# DA1470x register map
Vendor: Dialog; Series: DA1470x; File version: 1.2
CPU: CM33 r0p2, little endian, MPU, FPU, DSP, VTOR, 4 interrupt priority bits
Registers are 32-bit, read-write, reset 0x0 unless marked. A register's access mark holds for its fields unless they carry their own. Offsets are from the block's base; [hi:lo] are bit positions; {n}, {i} and the like mark numbered series.

## OQSPIF — OQSPIF registers
Base 0x36000000
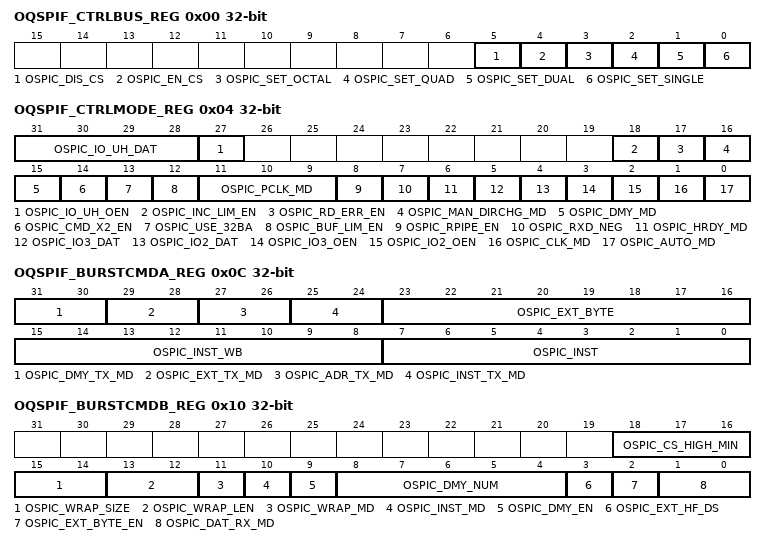
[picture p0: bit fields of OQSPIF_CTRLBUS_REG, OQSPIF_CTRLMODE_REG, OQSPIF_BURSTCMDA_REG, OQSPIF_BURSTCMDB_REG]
0x00 OQSPIF_CTRLBUS_REG — SPI Bus control register for the Manual mode
  [5] OSPIC_DIS_CS wo — Write 1 to disable the chip select (active low) when the controller is in Manual mode.
  [4] OSPIC_EN_CS wo — Write 1 to enable the chip select (active low) when the controller is in Manual mode.
  [3] OSPIC_SET_OCTAL wo — Write 1 to set the bus mode in Octal mode when the controller is in Manual mode.
  [2] OSPIC_SET_QUAD wo — Write 1 to set the bus mode in Quad mode when the controller is in Manual mode.
  [1] OSPIC_SET_DUAL wo — Write 1 to set the bus mode in Dual mode when the controller is in Manual mode.
  [0] OSPIC_SET_SINGLE wo — Write 1 to set the bus mode in Single SPI mode when the controller is in Manual mode.
0x04 OQSPIF_CTRLMODE_REG (reset mask 0x7FFFFFFF) — Mode Control register
  [31:28] OSPIC_IO_UH_DAT — The value of OSPI_IO4-7 pads if OSPI_IO_UH_OEN is 1
  [27] OSPIC_IO_UH_OEN — Forces the output enable for the upper half of the OSPI bus (OSPI_IO4-7). Set this bit to 1 only in SPI, Dual or Quad SPI mode to control the upper half of the OSPI bus. When the Octal SPI is enabled in the flash device, set this bit to zero. 0: The OSPI_IO4-7 pad direction is decided by the controller. 1: The OSPI_IO4-7 pad are outputs. The output values are defined by the corresponding OSPIC_IO_UH_DAT bits.
  [18] OSPIC_INC_LIM_EN — This bit has meaning only for the read in auto mode and only when the read access in the AHB bus is an incremental bust of unspecified length. 0: The length of the burst is considered as unspecified. The access in the flash device will be implemented as is defined by the OSPIC BUF_LIM_EN bit. 1: The length of the burst is considered as equal to 8-bytes. The access in the flash device will be implemented by the controller as one or more different bursts, until to be served the access in the AHB bus. Each burst in the flash device will have maximum length of 8 bytes. The setting OSPIC_INC_LIM_EN=1 is useful if we know that the masters that make use of the incremental burst of unspecified length, require no more than 8 bytes.
  [17] OSPIC_RD_ERR_EN — Controls the generation of AHB bus error response when a read is performed in the address space where the flash device is mapped and the Auto mode is not enabled. 0: The controller ignores the access. There is no error response due to the read access. 1: The controller responds with an AHB error response.
  [16] OSPIC_MAN_DIRCHG_MD — Selection of the direction change method in manual mode. 0 : the bus direction goes to input after each access 1 : the bus direction goes to input only after a dummy access
  [15] OSPIC_DMY_MD — Defines the clock cycle where the bus will turn in Hi-z during the transmission of dummy bytes. This is applicable in both Manual and Auto mode. 0 : the bus will become Hi-Z on the last clock 1 : the bus will become Hi-Z on the last two clocks
  [14] OSPIC_CMD_X2_EN — Defines the number of bytes that consist the instruction code in the command sequences that produced by the OSPIC during Auto mode. 0 : The instruction code is one byte only. 1 : The instruction code is two bytes. The second byte of the instruction code is the inverse of the first byte. The command sequence that is produced by the OSPIC_BURSTBRK_REG is not affected by this setting.
  [13] OSPIC_USE_32BA — Controls the length of the address that the external memory device uses. 0: The external memory device uses 24 bits address. 1: The external memory device uses 32 bits address. The controller uses this bit in order to decide the number of the address bytes that has to transfer to the external device during Auto mode.
  [12] OSPIC_BUF_LIM_EN — This bit has meaning only for the read in auto mode. Defines the behavior of the controller when the internal buffer is full and there are more data to be retrieved for the current burst. 0: The access in the flash device is not terminated when the internal buffer has no empty space. In this case the OSPI_SCK clock is blocked until to free space in the internal buffer. 1: The access in the flash device is terminated when the internal buffer has no empty space. A new access in the flash device will be initiated when will be requested addresses that are not present in the internal buffer. In both cases the access in the flash device is terminated when there is no any read request.
  [11:9] OSPIC_PCLK_MD — Read pipe clock delay relative to the falling edge of OSPI_SCK. Refer to OSPI Timing for timing parameters and recommended values: 0 to 7
  [8] OSPIC_RPIPE_EN — Controls the use of the data read pipe. 0: The read pipe is disabled; the sampling clock is defined according to the OSPIC_RXD_NEG setting. 1: The read pipe is enabled. The delay of the sampling clock is defined according to the OSPICI_PCLK_MD setting. (Recommended)
  [7] OSPIC_RXD_NEG — Defines the clock edge that is used for the capturing of the received data, when the read pipe is not active (OSPIC_RPIPE_EN = 0). 0: Sampling of the received data with the positive edge of the OSPI_SCK 1: Sampling of the received data with the negative edge of the OSPI_SCK The internal OSPI_SCK clock that is used by the controller for the capturing of the received data has a skew in respect of the OSPI_SCK that is received by the external memory device. In order to be improved the timing requirements of the read path, the controller supports a read pipe register with programmable clock delay. See also the OSPIC_RPIPE_EN register.
  [6] OSPIC_HRDY_MD — This configuration bit is useful when the frequency of the OSPI clock is much lower than the clock of the AMBA bus, in order to not locks the AMBA bus for a long time. 0: Adds wait states via hready signal when an access is performed on the OSPIC_CTRLBUS_REG, OSPIC_WRITEDATA, OSPIC_READDATA and OSPIC_DUMMYDATA registers. It is not needed to check the OSPIC_BUSY of the OSPIC_STATUS_REG. 1: The controller don't adds wait states via the hready signal, when is performed access on the OSPIC_CTRLBUS_REG, OSPIC_WRITEDATA, OSPIC_READDATA and OSPIC_DUMMYDATA registers. The OSPIC_BUSY bit of the OSPIC_STATUS_REG must be checked in order to be detected the completion of the requested access. It is applicable only when the controller is in Manual mode. In the case of the Auto mode, the controller always adds wait states via the hready signal.
  [5] OSPIC_IO3_DAT — The value of OSPI_IO3 pad if OSPI_IO3_OEN is 1
  [4] OSPIC_IO2_DAT — The value of OSPI_IO2 pad if OSPI_IO2_OEN is 1
  [3] OSPIC_IO3_OEN — Forces the output enable of the OSPI_IO3. Set this bit to 1 only in SPI or Dual SPI mode to control the /HOLD signal. When the Quad or Octal SPI is enabled in the flash device, set this bit to zero. 0: The OSPI_IO3 pad direction is decided by the controller. 1: The OSPI_IO3 pad is output. The output value is defined by the OSPIC_IO3_DAT.
  [2] OSPIC_IO2_OEN — Forces the output enable of the OSPI_IO2. Set this bit to 1 only in SPI or Dual SPI mode to control the /WP signal. When the Quad or Octal SPI is enabled in the flash device, set this bit to zero. 0: The OSPI_IO2 pad direction is decided by the controller. 1: The OSPI_IO2 pad is output. The output value is defined by the OSPIC_IO2_DAT.
  [1] OSPIC_CLK_MD — Mode of the generated OSPI_SCK clock 0: Use Mode 0 for the OSPI_CLK. The OSPI_SCK is low when OSPI_CS is high. 1: Use Mode 3 for the OSPI_CLK. The OSPI_SCK is high when OSPI_CS is high.
  [0] OSPIC_AUTO_MD — Mode of operation 0: The Manual Mode is selected. 1: The Auto Mode is selected. During an erasing the OSPIC_AUTO_MD goes in read only mode (see OSPIC_ERASE_EN)
0x08 OQSPIF_RECVDATA_REG (reset mask 0x7FFFFFFF) — Received data for the Manual mode
  [31:0] OSPIC_RECVDATA ro — This register contains the received data when the OSPIC_READDATA_REG register is used in Manual mode, in order to be retrieved data from the external memory device and OSPIC_HRDY_MD=1 && OSPIC_BUSY=0.
0x0C OQSPIF_BURSTCMDA_REG (reset mask 0x7FFFFFFF) — The way of reading in Auto mode (command register A)
  [31:30] OSPIC_DMY_TX_MD — It describes the mode of the SPI bus during the Dummy bytes phase. 0x0: Single SPI 0x1: Dual 0x2: Quad 0x3: Octal
  [29:28] OSPIC_EXT_TX_MD — It describes the mode of the SPI bus during the Extra Byte phase. 0x0: Single SPI 0x1: Dual 0x2: Quad 0x3: Octal
  [27:26] OSPIC_ADR_TX_MD — It describes the mode of the SPI bus during the address phase. 0x0: Single SPI 0x1: Dual 0x2: Quad 0x3: Octal
  [25:24] OSPIC_INST_TX_MD — It describes the mode of the SPI bus during the instruction phase. 0x0: Single SPI 0x1: Dual 0x2: Quad 0x3: Octal
  [23:16] OSPIC_EXT_BYTE — The value of an extra byte which will be transferred after address (only if OSPIC_EXT_BYTE_EN= 1). Usually this is the Mode Bits in Dual/Quad/Octal SPI I/O instructions.
  [15:8] OSPIC_INST_WB — Instruction Value for Wrapping Burst. This value is the selected instruction when OSPIC_WRAP_MD is equal to 1 and the access is a wrapping burst of length and size described by the bit fields OSPIC_WRAP_LEN and OSPIC_WRAP_SIZE respectively.
  [7:0] OSPIC_INST — Instruction Value for Incremental Burst or Single read access. This value is the selected instruction at the cases of incremental burst or single read access. Also this value is used when a wrapping burst is not supported (OSPIC_WRAP_MD)
0x10 OQSPIF_BURSTCMDB_REG — The way of reading in Auto mode (command register B)
  [18:16] OSPIC_CS_HIGH_MIN — Between the transmissions of two different instructions to the flash memory, the SPI bus stays in idle state (OSPI_CS high) for at least this number of OSPI_SCK clock cycles. See the OSPIC_ERS_CS_HI register for some exceptions.
  [15:14] OSPIC_WRAP_SIZE — It describes the selected data size of a wrapping burst (OSPIC_WRAP_MD). 0x0: byte access (8-bits) 0x1: half word access (16 bits) 0x2: word access (32-bits) 0x3: Reserved
  [13:12] OSPIC_WRAP_LEN — It describes the selected length of a wrapping burst (OSPIC_WRAP_MD). 0x0: 4 beat wrapping burst 0x1: 8 beat wrapping burst 0x2: 16 beat wrapping burst 0x3: Reserved
  [11] OSPIC_WRAP_MD — Wrap mode 0: The OSPIC_INST is the selected instruction at any access. 1: The OSPIC_INST_WB is the selected instruction at any wrapping burst access of length and size described by the registers OSPIC_WRAP_LEN and OSPIC_WRAP_SIZE respectively. In all other cases the OSPIC_INST is the selected instruction. Use this feature only when the serial FLASH memory supports a special instruction for wrapping burst access.
  [10] OSPIC_INST_MD — Instruction mode 0: Transmit instruction at any burst access. 1: Transmit instruction only in the first access after the selection of Auto Mode.
  [9] OSPIC_DMY_EN — Dummy bytes enable 0: Don't send the dummy bytes 1: Send the dummy bytes. The number of the dummy bytes is defined by the OSPIC_DMY_NUM.
  [8:4] OSPIC_DMY_NUM — Number of dummy bytes (minus 1). Can be set 1 up to 32 dummy bytes (values 0 up to 31). The dummy bytes are appied only when OSPIC_DMY_EN=1.
  [3] OSPIC_EXT_HF_DS — Extra half disable output 0: if OSPIC_EXT_BYTE_EN=1, is transmitted the complete OSPIC_EXT_BYTE 1: if OSPIC_EXT_BYTE_EN=1, the output is disabled (hi-z) during the transmission of bits [3:0] of OSPIC_EXT_BYTE. This setting has no meaning if the extra byte is transferred in Octal mode. In this case keep this bit to zero value.
  [2] OSPIC_EXT_BYTE_EN — Extra byte enable 0: Don't send the OSPIC_EXT_BYTE 1: Send the OSPIC_EXT_BYTE
  [1:0] OSPIC_DAT_RX_MD — It describes the mode of the SPI bus during the data phase. 0x0: Single SPI 0x1: Dual 0x2: Quad 0x3: Octal
0x14 OQSPIF_STATUS_REG — The status register of the OSPI controller
  [0] OSPIC_BUSY ro — The status of the SPI Bus. 0: The SPI Bus is idle 1: The SPI Bus is active. Read data, write data or dummy data activity is in progress. Has meaning only in Manual mode and only when OSPIC_HRDY_MD = 1.
0x18 OQSPIF_WRITEDATA_REG (reset mask 0x7FFFFFFF) — Write data to SPI Bus for the Manual mode
  [31:0] OSPIC_WRITEDATA wo — Writing to this register is generating a data transfer from the controller to the external memory device. The data written in this register, is then transferred to the memory using the selected mode of the SPI bus (Single SPI, Dual SPI, Quad SPI or Octal SPI). The data size of the access to this register can be 32-bits / 16-bits/ 8-bits and is equal to the number of the transferred bits. This register has meaning only when the controller is in Manual mode.
0x1C OQSPIF_READDATA_REG (reset mask 0x7FFFFFFF) — Read data from SPI Bus for the Manual mode
  [31:0] OSPIC_READDATA ro — A read access at this register generates a data transfer from the external memory device to the OSPIC controller. The data is transferred using the selected mode of the SPI bus (Single SPI, Dual SPI, Quad SPI or Octal SPI). The data size of the access to this register can be 32-bits / 16-bits / 8-bits and is equal to the number of the transferred bits. This register has meaning only when the controller is in Manual mode.
0x20 OQSPIF_DUMMYDATA_REG (reset mask 0x7FFFFFFF) — Send dummy clocks to SPI Bus for the Manual mode
  [31:0] OSPIC_DUMMYDATA wo — Writing to this register generates a number of clock pulses to the SPI bus. During the last clock of this activity in the SPI bus, the OSPI_IOx data pads are in hi-z state (see also the OSPIC_DMY_MD). The data size of the access to this register can be 32-bits / 16-bits/ 8-bits. The number of generated pulses is equal to: (size of AHB bus access) / (size of SPI bus). The size of SPI bus is equal to 1, 2, 4 or 8 for Single, Dual, Quad or Octal SPI mode respectively. This register has meaning only when the controller is in Manual mode.
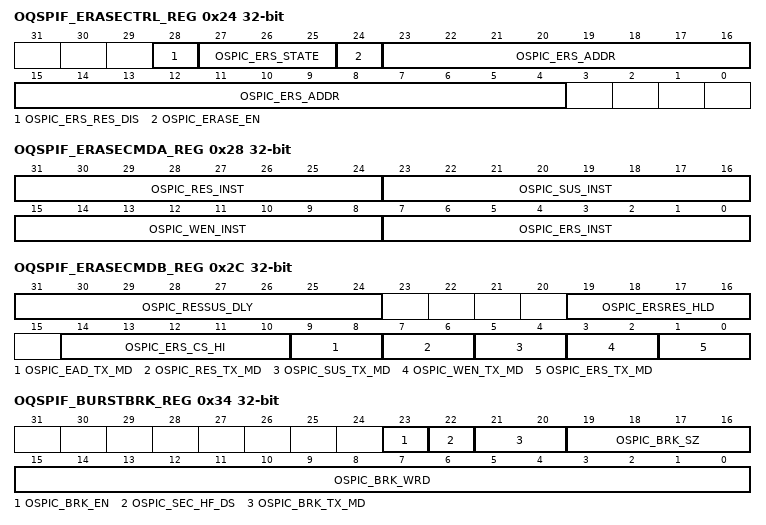
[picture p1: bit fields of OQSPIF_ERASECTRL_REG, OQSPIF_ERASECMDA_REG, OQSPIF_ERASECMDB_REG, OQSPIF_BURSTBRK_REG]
0x24 OQSPIF_ERASECTRL_REG — OSPI Erase control register
  [28] OSPIC_ERS_RES_DIS — This configuration bit has meaning when an erase has been suspended. Normally the erase will be resumed when the flash will stay idle (without read accesses) for a predefined number of clock cycles (see OSPIC_ERASECMDB_REG [OSPIC_ERSRES_HLD]). By setting this bit the execution of the erase resume process can be postponed. 0: A suspended erase will be resumed based on the setting in the OSPIC_ERSRES_HLD. 1: The erase will not be resumed even after the expiration of the OSPIC_ERSRES_HLD. The erase can be resumed again only when the OSPIC_ERS_RES_DIS=0.
  [27:25] OSPIC_ERS_STATE ro — It shows the progress of sector/block erasing (read only). 0x0: No Erase. 0x1: Pending erase request 0x2: Erase procedure is running 0x3: Suspended Erase procedure 0x4: Finishing the Erase procedure 0x5..0x7: Reserved
  [24] OSPIC_ERASE_EN — During Manual mode (OSPIC_AUTO_MD = 0). This bit is in read only mode. During Auto mode (OSPIC_AUTO_MD = 1). To request the erasing of the block/sector (OSPIC_ERS_ADDR, 12'b0) write 1 to this bit. This bit is cleared automatically with the end of the erasing. Until the end of erasing the OSPIC_ERASE_EN remains in read only mode. During the same time interval the controller remains in Auto Mode (OSPIC_AUTO_MD goes in read only mode).
  [23:4] OSPIC_ERS_ADDR — Defines the address of the block/sector that is requested to be erased. If OSPIC_USE_32BA = 0 (24 bits addressing), bits OSPIC_ERASECTRL_REG[23-12] determine the block/ sector address bits [23-12]. The OSPIC_ERASECTRL_REG[11-4] are ignored by the controller. If OSPIC_USE_32BA = 1 (32 bits addressing) bits OSPIC_ERASECTRL_REG[23-4] determine the block / sectors address bits [31:12]
0x28 OQSPIF_ERASECMDA_REG (reset mask 0x7FFFFFFF) — The way of erasing in Auto mode (command register A)
  [31:24] OSPIC_RES_INST — The code value of the erase resume instruction
  [23:16] OSPIC_SUS_INST — The code value of the erase suspend instruction.
  [15:8] OSPIC_WEN_INST — The code value of the write enable instruction.
  [7:0] OSPIC_ERS_INST — The code value of the erase instruction.
0x2C OQSPIF_ERASECMDB_REG (reset mask 0x7FFFFFFF) — The way of erasing in Auto mode (command register B)
  [31:24] OSPIC_RESSUS_DLY — Defines a timer that counts the minimum allowed delay between an erase suspend command and the previous erase resume command (or the initial erase command). 0: Don't wait. The controller starts immediately to suspend the erase procedure. 1..255: The controller waits for at least this number of 222kHz clock cycles before the suspension of erasing. Time starts counting after the end of the previous erase resume command (or the initial erase command)
  [19:16] OSPIC_ERSRES_HLD — The controller must stay without flash memory reading requests for this number of AMBA hclk clock cycles, before to perform the command of erase or erase resume 15 - 0
  [14:10] OSPIC_ERS_CS_HI — After the execution of instructions: write enable, erase, erase suspend and erase resume, the OSPI_CS remains high for at least this number of OSPI bus clock cycles.
  [9:8] OSPIC_EAD_TX_MD — The mode of the OSPI Bus during the address phase of the erase instruction 0x0: Single 0x1: Dual 0x2: Quad 0x3: Octal
  [7:6] OSPIC_RES_TX_MD — The mode of the OSPI Bus during the transmission of the resume instruction 0x0: Single 0x1: Dual 0x2: Quad 0x3: Octal
  [5:4] OSPIC_SUS_TX_MD — The mode of the OSPI Bus during the transmission of the suspend instruction. 0x0: Single 0x1: Dual 0x2: Quad 0x3: Octal
  [3:2] OSPIC_WEN_TX_MD — The mode of the OSPI Bus during the transmission of the write enable instruction. 0x0: Single 0x1: Dual 0x2: Quad 0x3: Octal
  [1:0] OSPIC_ERS_TX_MD — The mode of the OSPI Bus during the instruction phase of the erase instruction 0x0: Single 0x1: Dual 0x2: Quad 0x3: Octal
0x30 OQSPIF_ERASECMDC_REG — The way of erasing in Auto mode (command register C)
  [5:0] OSPIC_SUSSTS_DLY — Defines a timer that counts the minimum allowed delay between an erase suspend command and the next read status command. 0: Don't wait. The controller starts immediately to read the status of the flash device. 1..63: The controller waits for at least this number of 222kHz clock cycles before to read the status of the flash device. Time starts counting when the erase resume command is applied.
0x34 OQSPIF_BURSTBRK_REG — Read break sequence in Auto mode
  [23] OSPIC_BRK_EN — Controls the application of a special command (read burst break sequence) that is used in order to force the device to abandon the continuous read mode. 0: The special command is not applied 1: The special command is applied This special command is applied by the controller to the external device under the following conditions: - the controller is in Auto mode - the OSPIC_INST_MD = 1 - the previous command that has been applied in the external device was read - the controller want to apply to the external device a command different than the read.
  [22] OSPIC_SEC_HF_DS — Disable output during the transmission of the second half (OSPIC_BRK_WRD[3:0]). Setting this bit is only useful if OSPIC_BRK_EN =1 and OSPIC_BRK_SZ >= 1. It is not applicable when the sequence is transferred in Octal mode (OSPIC_BRK_TX_MD=3). 0: The controller drives the OSPI bus during the transmission of the OSPIC_BRK_WRD[3:0]. 1: The controller leaves the OSPI bus in Hi-Z during the transmission of the OSPIC_BRK_WORD[3:0].
  [21:20] OSPIC_BRK_TX_MD — The mode of the OSPI Bus during the transmission of the burst break sequence. 0x0: Single 0x1: Dual 0x2: Quad 0x3: Octal
  [19:16] OSPIC_BRK_SZ — The size of Burst Break Sequence 0: One byte (Send OSPIC_BRK_WRD[15:8]) 1: Two bytes (Send OSPIC_BRK_WRD[15:0]) 2-15: Three up to 16 bytes will be transferred. All the bytes that will be transferred will have the value of the OSPIC_BRK_WRD[15:8], except of the last byte that will be the OSPIC_BRK_WRD[7:0].
  [15:0] OSPIC_BRK_WRD — This is the value of a special command (read burst break sequence) that is applied by the controller to the external memory device, in order to force the memory device to abandon the continuous read mode.
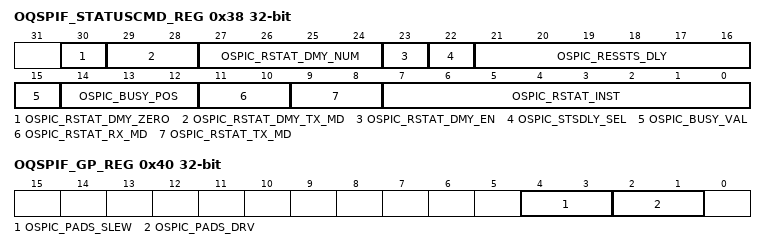
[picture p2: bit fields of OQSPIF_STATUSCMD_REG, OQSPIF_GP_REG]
0x38 OQSPIF_STATUSCMD_REG — The way of reading the status of external device in Auto mode
  [30] OSPIC_RSTAT_DMY_ZERO — Defines the value of that is transferred on the OSPI bus during the phase of the dummy bytes. 0: The controller keeps the data in the bus unchanged, until to change the bus direction in input mode. 1: Forces the dummy bytes to get the zero value (only for the cycles that are not in input mode). Only the IO pins that are related with the transfer mode of the dummy bytes (OSPIC_RSTAT_DMY_TX_MD) will get the zero value.
  [29:28] OSPIC_RSTAT_DMY_TX_MD — It describes the mode of the OSPI bus during the dummy bytes phase. 0x0: Single SPI 0x1: Dual 0x2: Quad 0x3: Octal
  [27:24] OSPIC_RSTAT_DMY_NUM — Number of dummy bytes (minus 1). Can be set 1 up to 16 dummy bytes (values 0 up to 15). The dummy bytes are applied only when OSPIC_RSTAT_DMY_EN=1.
  [23] OSPIC_RSTAT_DMY_EN — Enables the transmission of dummy bytes, immediately after the instruction code of the read status command. 0: Don't send the dummy bytes 1: Send the dummy bytes. The number of the dummy bytes is defined by the OSPIC_RSTAT_DMY_NUM.
  [22] OSPIC_STSDLY_SEL — Defines the timer which is used to count the delay that it has to wait before to read the FLASH Status Register, after an erase or an erase resume command. 0: The delay is controlled by the OSPIC_RESSTS_DLY which counts on the OSPI_CLK clock. 1: The delay is controlled by the OSPIC_RESSUS_DLY which counts on the 222 kHz clock.
  [21:16] OSPIC_RESSTS_DLY — Defines a timer that counts the minimum required delay between the reading of the status register and of the previous erase or erase resume instruction. 0: Don't wait. The controller starts to reading the Flash memory status register immediately. 1..63: The controller waits for at least this number of OSPI_CLK cycles and afterwards it starts to reading the Flash memory status register. The timer starts to count after the end of the previous erase or erase resume command. The actual timer that will be used by the controller before the reading of the Flash memory status register is defined by the OSPIC_STSDLY_SEL.
  [15] OSPIC_BUSY_VAL — Defines the value of the Busy bit which means that the flash is busy. 0: The flash is busy when the Busy bit is equal to 0. 1: The flash is busy when the Busy bit is equal to 1.
  [14:12] OSPIC_BUSY_POS — It describes who from the bits of status represents the Busy bit (7 - 0).
  [11:10] OSPIC_RSTAT_RX_MD — The mode of the OSPI Bus during the receive status phase of the read status instruction 0x0: Single 0x1: Dual 0x2: Quad 0x3: Octal
  [9:8] OSPIC_RSTAT_TX_MD — The mode of the OSPI Bus during the instruction phase of the read status instruction. 0x0: Single 0x1: Dual 0x2: Quad 0x3: Octal
  [7:0] OSPIC_RSTAT_INST — The code value of the read status instruction. It is transmitted during the instruction phase of the read status instruction.
0x3C OQSPIF_CHCKERASE_REG (reset mask 0x7FFFFFFF) — Check erase progress in Auto mode
  [31:0] OSPIC_CHCKERASE wo — Writing any value to this register during erasing, forces the controller to read the flash memory status register. Depending on the value of the Busy bit, it updates the OSPIC_ERASE_EN.
0x40 OQSPIF_GP_REG — OSPI General Purpose control register
  [4:3] OSPIC_PADS_SLEW — QSPI pads slew rate control. Indicative values under certain conditions: 0: Rise=1.7 V/ns, Fall=1.9 V/ns (weak) 1: Rise=2.0 V/ns, Fall=2.3 V/ns 2: Rise=2.3 V/ns, Fall=2.6 V/ns 3: Rise=2.4 V/ns, Fall=2.7 V/ns (strong) Conditions: FLASH pin capacitance 6 pF, Vcc=1.8V, T=25C and Idrive=16mA.
  [2:1] OSPIC_PADS_DRV — QSPI pads drive current 0: 4 mA 1: 8 mA 2: 12 mA 3: 16 mA
0x100 OQSPIF_CTR_CTRL_REG — Control register for the decryption engine of the OSPIC
  [0] OSPIC_CTR_EN — Controls the AES-CTR decryption feature of the OSPIC, which enables the decryption (on-the-fly) of the data that are retrieved from the flash memory device. 0: The AES-CTR decryption is disabled. 1: The controller will decrypt the content of the flash memory device that is placed in the address space that is defined by the OSPIC_CTR_SADDR_REG and OSPIC_CTR_EADDR_REG registers. The data that are placed outside the previous space are not decrypted by the OSPIC. The decryption is performed by using the AES-CTR algorithm. The AES key is defined by the OSPIC_CTR_KEY_x_y_REG registers and the nonce value by the OSPIC_CTR_NONCE_x_y_REG registers. This configuration bit has meaning only while the controller is in Auto mode. The on-the-fly decryption is not provided in Manual mode.
0x104 OQSPIF_CTR_SADDR_REG (reset mask 0x7FFFFFFF) — Start address of the encrypted content in the OSPI flash
  [31:10] OSPIC_CTR_SADDR — Defines the bits [31:10] of the start address in the flash memory, where an encrypted image is placed. The bits [9:0] are considered always as zero. This has meaning only when the decryption is active. See also the register OSPIC_CTR_CTRL_REG[OSPIC_CTR_EN].
0x108 OQSPIF_CTR_EADDR_REG reset 0x3FF (reset mask 0x7FFFFFFF) — End address of the encrypted content in the OSPI flash
  [31:10] OSPIC_CTR_EADDR — Defines the bits [31:10] of the end address in the flash memory, where an encrypted image is placed. The bits [9:0] are considered always as 0x3ff. This has meaning only when the decryption is active. See also the register OSPIC_CTR_CTRL_REG[OSPIC_CTR_EN].
0x10C OQSPIF_CTR_NONCE_0_3_REG (reset mask 0x7FFFFFFF) — Nonce bytes 0 to 3 for the AES-CTR algorithm
  [31:0] OSPIC_CTR_NONCE_0_3 — Defines the 8 bytes of the nonce value (N0 - N7) that is used by the AES-CTR algorithm in order to be constructed the counter block (CTRB). The total size of the counter block is 128 bits or 16 bytes : CTRB0 CTRB1 CTRB2 CTRB3...CTRB14 CTRB15. The first 8 bytes (CTRB0 - CTRB7) of the counter block consisted by the nonce value. The next 8 bytes of the counter block (CTRB8-CTRB15), are produced automatically by the hardware based on the address offset inside the encrypted image, from where are retrieved the requested data. The mapping of the nonce bytes to the corresponding OSPIC_NONCE_X_Y_REG registers is the following : {CTRB0, CTRB1, CTRB2, CTRB3} = {N0, N1, N2, N3} = OSPIC_NONCE_0_3_REG[31:0] {CTRB4, CTRB5, CTRB6, CTRB7} = {N4, N5, N6, N7} = OSPIC_NONCE_4_7_REG[31:0] All these registers make sense only when OSPIC_CTR_CTRL_REG[OSPIC_CTR_EN] = 1. Do not perform access to an encrypted address range while the updating process of the nonce value is in progress.
0x110 OQSPIF_CTR_NONCE_4_7_REG (reset mask 0x7FFFFFFF) — Nonce bytes 4 to 7 for the AES-CTR algorithm
  [31:0] OSPIC_CTR_NONCE_4_7 — See the description in the OSPIC_NONCE_0_3.
0x114 OQSPIF_CTR_KEY_0_3_REG (reset mask 0x7FFFFFFF) — Key bytes 0 to 3 for the AES-CTR algorithm
  [31:0] OSPIC_CTR_KEY_0_3 wo — Defines the key that is used by the AES-CTR algorithm, when the on-the-fly decryption is enabled ( OSPIC_CTR_CTRL_REG[OSPIC_CTR_EN] = 1 ). The size of the decryption key is 256bits or 32 bytes : K0 K1 K2 K3...K30 K31. The mapping of the bytes to the corresponding OSPIC_CTR_KEY_X_Y_REG registers is the following : {K0, K1, K2, K3} = OSPIC_CTR_KEY_0_3_REG[31:0] {K4, K5, K6, K7} = OSPIC_CTR_KEY_4_7_REG[31:0] {K8, K9, K10, K11} = OSPIC_CTR_KEY_8_11_REG[31:0] {K12, K13, K14, K15} = OSPIC_CTR_KEY_12_15_REG[31:0] {K16, K17, K18, K19} = OSPIC_CTR_KEY_16_19_REG[31:0] {K20, K21, K22, K23} = OSPIC_CTR_KEY_20_23_REG[31:0] {K24, K25, K26, K27} = OSPIC_CTR_KEY_24_27_REG[31:0] {K28, K29, K30, K31} = OSPIC_CTR_KEY_28_31_REG[31:0] All these registers make sense only when OSPIC_CTR_CTRL_REG[OSPIC_CTR_EN] = 1. Do not perform access to an encrypted address range while the updating process of the decryption key is in progress.
0x118 OQSPIF_CTR_KEY_4_7_REG (reset mask 0x7FFFFFFF) — Key bytes 4 to 7 for the AES-CTR algorithm
  [31:0] OSPIC_CTR_KEY_4_7 wo — See the description in the OSPIC_CTR_KEY_0_3.
0x11C OQSPIF_CTR_KEY_8_11_REG (reset mask 0x7FFFFFFF) — Key bytes 8 to 11 for the AES-CTR algorithm
  [31:0] OSPIC_CTR_KEY_8_11 wo — See the description in the OSPIC_CTR_KEY_0_3.
0x120 OQSPIF_CTR_KEY_12_15_REG (reset mask 0x7FFFFFFF) — Key bytes 12 to 15 for the AES-CTR algorithm
  [31:0] OSPIC_CTR_KEY_12_15 wo — See the description in the OSPIC_CTR_KEY_0_3.
0x124 OQSPIF_CTR_KEY_16_19_REG (reset mask 0x7FFFFFFF) — Key bytes 16 to 19 for the AES-CTR algorithm
  [31:0] OSPIC_CTR_KEY_16_19 wo — See the description in the OSPIC_CTR_KEY_0_3.
0x128 OQSPIF_CTR_KEY_20_23_REG (reset mask 0x7FFFFFFF) — Key bytes 20 to 23 for the AES-CTR algorithm
  [31:0] OSPIC_CTR_KEY_20_23 wo — See the description in the OSPIC_CTR_KEY_0_3.
0x12C OQSPIF_CTR_KEY_24_27_REG (reset mask 0x7FFFFFFF) — Key bytes 24 to 27 for the AES-CTR algorithm
  [31:0] OSPIC_CTR_KEY_24_27 wo — See the description in the OSPIC_CTR_KEY_0_3.
0x130 OQSPIF_CTR_KEY_28_31_REG (reset mask 0x7FFFFFFF) — Key bytes 28 to 31 for the AES-CTR algorithm
  [31:0] OSPIC_CTR_KEY_28_31 wo — See the description in the OSPIC_CTR_KEY_0_3.
